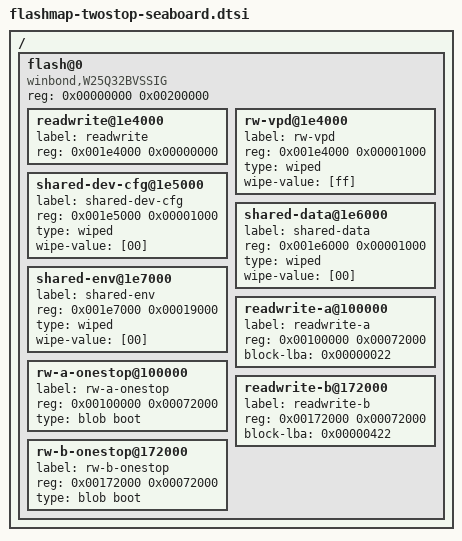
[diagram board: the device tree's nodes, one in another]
/*
 * Copyright (c) 2011 The Chromium OS Authors. All rights reserved.
 * Use of this source code is governed by a BSD-style license that can be
 * found in the LICENSE file.
 */

/*
 * This is the flash map (fmap) for a twostop firmware. It defines all the areas
 * that Chrome OS expects to find in its firmware device. The device is split
 * into a number of top-level sections, and within each are several areas.
 *
 * Available flags for each entry are: read-only, compresed.
 * All sections will be marked static in the fmap.
 */

/include/ "onestop-layout.dtsi"
/include/ "flashmap-twostop-ro-submap.dtsi"

/ {
	flash@0 {
		#address-cells = <1>;
		#size-cells = <1>;
		compatible = "winbond,W25Q32BVSSIG", "cfi-flash",
			     "chromeos,flashmap";
		reg = <0x00000000 0x00200000>;

		/* ---- Section: Readwrite ---- */
		readwrite@1e4000 {
			label = "readwrite";
			reg = <0x001e4000 0x00000000>;
		};
		rw-vpd@1e4000 {
			label = "rw-vpd";
			reg = <0x001e4000 0x00001000>;
			type = "wiped";
			wipe-value = [ff];
		};
		shared-dev-cfg@1e5000 {
			label = "shared-dev-cfg";
			reg = <0x001e5000 0x00001000>;
			type = "wiped";
			wipe-value = [00];
		};
		shared-data@1e6000 {
			label = "shared-data";
			reg = <0x001e6000 0x00001000>;
			type = "wiped";
			wipe-value = [00];
		};
		shared-env@1e7000 {
			label = "shared-env";
			reg = <0x001e7000 0x00019000>;

			/*
			 * We could put the dev environment here, but U-Boot
			 * has a default built in. Devs can 'saveenv' to set
			 * this up.
			 */
			type = "wiped";
			wipe-value = [00];
		};

		/* ---- Section: Readwrite Slot A and B ---- */
		/* So far only onestop is put into readwrite A/B section */
		readwrite-a@100000 {
			label = "readwrite-a";
			reg = <0x00100000 0x00072000>;
			block-lba = <0x00000022>;
		};
		rw-a-onestop@100000 {
			label = "rw-a-onestop";
			reg = <0x00100000 0x00072000>;
			type = "blob boot";
		};
		readwrite-b@172000 {
			label = "readwrite-b";
			reg = <0x00172000 0x00072000>;
			block-lba = <0x00000422>;
		};
		rw-b-onestop@172000 {
			label = "rw-b-onestop";
			reg = <0x00172000 0x00072000>;
			type = "blob boot";
		};
	};
};
